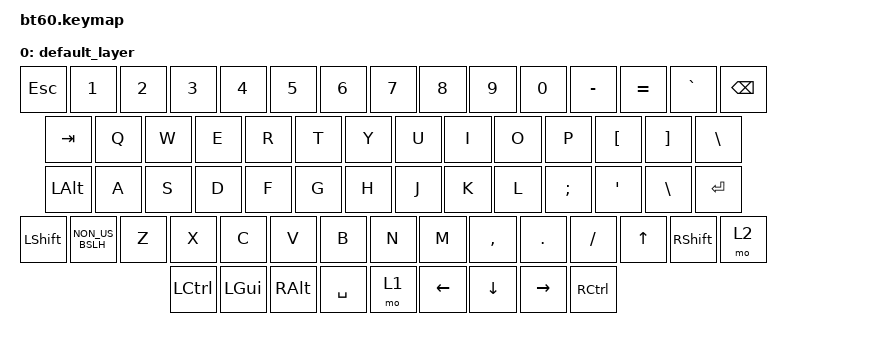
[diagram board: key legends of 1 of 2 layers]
#include <behaviors.dtsi>
#include <dt-bindings/zmk/keys.h>
#include <dt-bindings/zmk/bt.h>
#include <dt-bindings/zmk/rgb.h>
#include <dt-bindings/zmk/backlight.h>

/ {
	keymap {
		compatible = "zmk,keymap";

		default_layer {
				// ------------------------------------------------------------------------------------------
				// | ESC |  1  |  2  |  3  |  4  |  5  |  6  |  7  |  8  |  9  |  0  |  -  |  =  |BKSP | DEL |
				// | TAB  |  Q  |  W  |  E  |  R  |  T  |  Y  |  U  |  I  |  O  |  P  |  [  |  ]  |  |   |
				// | CAPS  |  A  |  S  |  D  |  F  |  G  |  H  |  J  |  K  |  L  |  ;  |  '  |     ENTER    |
				// |  SHIFT|NONE|  Z  |  X  |  C  |  V  |  B  |  N  |  M  |  ,  |  .  | /   | SHFT | UP | 1  |
				// |  CTL  |  WIN  |  ALT  |            SPACE              | ALT | CTRL | LEFT | DOWN | RIGHT |
				// ------------------------------------------------------------------------------------------
			bindings = <
				&kp ESC &kp N1 &kp N2 &kp N3 &kp N4 &kp N5 &kp N6 &kp N7 &kp  N8   &kp  N9 &kp  N0  &kp MINUS &kp EQUAL &kp GRAVE &kp BSPC
				&kp TAB  &kp Q  &kp W  &kp E  &kp R  &kp T  &kp Y  &kp U  &kp  I    &kp  O  &kp  P   &kp LBKT &kp RBKT  &kp BSLH
				&kp LALT  &kp A  &kp S  &kp D  &kp F  &kp G  &kp H  &kp J  &kp  K    &kp  L  &kp SEMI &kp SQT &kp BSLH  &kp RET
				&kp LSHFT &kp NON_US_BSLH &kp Z  &kp X  &kp C  &kp V  &kp B  &kp N  &kp M  &kp COMMA &kp DOT &kp FSLH   &kp UP &kp RSHFT &mo 2
				&kp LCTRL &kp LGUI &kp RALT            &kp SPACE                          &mo 1  &kp LEFT &kp DOWN &kp RIGHT &kp RCTRL
			>;
			sensor-bindings = <&inc_dec_kp C_VOL_UP C_VOL_DN>;
		};
		raise {
			bindings = <
				&kp GRAVE &kp F1 &kp F2 &kp F3 &kp F4 &kp F5 &kp F6 &kp F7 &kp  F8   &kp  F9 &kp  F10  &kp F11 &kp F12   &trans &kp DEL
				&trans &trans &kp UP &bt BT_CLR &reset &rgb_ug RGB_TOG &trans &trans &kp INS &trans &kp PSCRN &kp SLCK &kp PAUSE_BREAK
				&trans    &kp LEFT &kp DOWN &kp RIGHT &trans &trans &trans &trans &trans &trans &trans  &trans   &bootloader
				&trans &kp C_PREV &kp C_VOL_DN &kp C_VOL_UP &kp C_MUTE &trans &bl BL_TOG &trans &trans &trans &trans &trans &trans &kp PG_UP &trans
				&bt BT_PRV &bt BT_NXT  &trans              &trans                            &trans  &kp HOME   &kp PG_DN &kp END &trans
			>;
			sensor-bindings = <&inc_dec_kp C_VOL_UP C_VOL_DN>;
		};
	};
};
